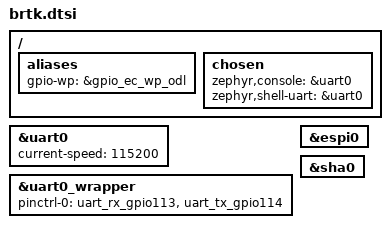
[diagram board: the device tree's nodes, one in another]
/* Copyright 2025 The ChromiumOS Authors
 * Use of this source code is governed by a BSD-style license that can be
 * found in the LICENSE file.
 */

/ {
	aliases {
		gpio-wp = &gpio_ec_wp_odl;
	};
	chosen {
		zephyr,console = &uart0;
		zephyr,shell-uart = &uart0;
	};
};

/* UART interface is gpio113.114 */
&uart0 {
	status = "okay";
	current-speed = <115200>;
};

&uart0_wrapper {
	status = "okay";
	pinctrl-0 = <&uart_rx_gpio113 &uart_tx_gpio114>;
	pinctrl-names = "default";
};

&espi0 {
	status = "okay";
};

&sha0 {
	status = "okay";
};
